# PLLCTRL0 register map
Vendor: Texas Instruments
Peripheral module from a debugger description file (folder J7ES).
Registers are 32-bit, access per field, reset 0x0 unless marked. A register's access mark holds for its fields unless they carry their own. Offsets are as the file gives them; lines under a group give offsets from that group; [hi:lo] are bit positions; {n}, {i} and the like mark numbered series; 'fields as' and 'values as' point back to an identical list; <NAME> marks a mode.

## PLLCTRL0
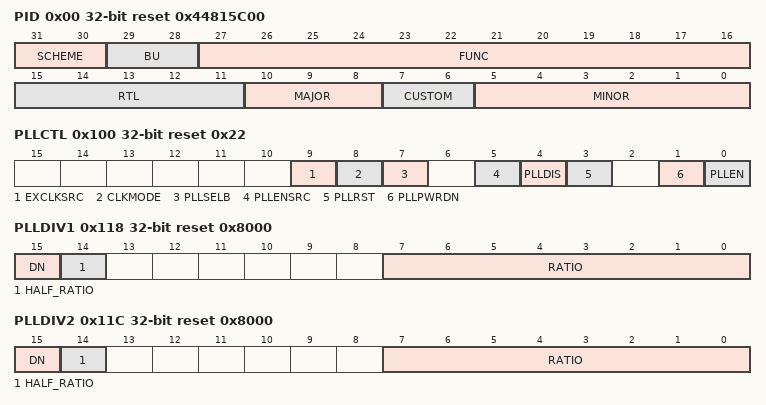
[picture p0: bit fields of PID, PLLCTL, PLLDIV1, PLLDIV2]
0x00 PID ro reset 0x44815C00 — register
  [31:30] SCHEME
  [29:28] BU — Business Unit
  [27:16] FUNC — Module ID
  [15:11] RTL — RTL revision.
  [10:8] MAJOR — Major revision
  [7:6] CUSTOM
  [5:0] MINOR — Minor revision
0x100 PLLCTL rw reset 0x22 (reset mask 0xFFFFFEE7) — PLL control register
  [9] EXCLKSRC — Selects between using bypass clock or an external clock source.
  [8] CLKMODE — Reference Clock Selection.
  [7] PLLSELB — Selects PLL A versus PLL B.
  [5] PLLENSRC — PLLEN Mux Control Source
  [4] PLLDIS — Asserts DISABLE to PLL if Supported
  [3] PLLRST — Asserts RESET to PLL if Supported.
  [1] PLLPWRDN — Selects PLL Power Down for the PLL selected by PLLSELB.
  [0] PLLEN — PLL Mode Enable
0x118 PLLDIV1 reset 0x8000 (reset mask 0xFFFFFF00) — PLL controller divider1 control register
  [15] DN ro — Divider Dn Enable
  [14] HALF_RATIO rw — Ratio is in half steps.
  [7:0] RATIO rw — Divider Dn Ratio (SYSCLKn divider)
0x11C PLLDIV2 reset 0x8000 (reset mask 0xFFFFFF00) — PLL controller divider2 control register
  fields as PLLDIV1
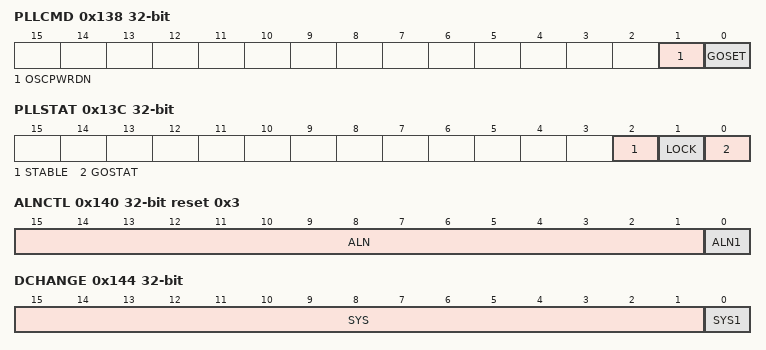
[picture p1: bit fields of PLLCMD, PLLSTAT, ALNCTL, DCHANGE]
0x138 PLLCMD rw — PLL Controller command register
  [1] OSCPWRDN — iOscillator Power Down Command
  [0] GOSET — GO bit for SYSCLKx phase alignment.
0x13C PLLSTAT (reset mask 0xFFFFFFFB) — PLL Controller status register
  [2] STABLE ro — OSCIN Stable
  [1] LOCK ro — PLL Core STATUS
  [0] GOSTAT ro — Reflects the status of GO transition.
0x140 ALNCTL rw reset 0x3 — PLL Controller clock align control register
  [15:1] ALN — SYSCLKx needs to be aligned with other clocks selected in this register.
  [0] ALN1 — SYSCLK1 needs to be aligned with other clocks selected in this register.
0x144 DCHANGE — PLLDIV ratio change register
  [15:1] SYS ro — SYSCLKx divide ratio has been modified.
  [0] SYS1 ro — SYSCLK1 divide ratio has been modified.
